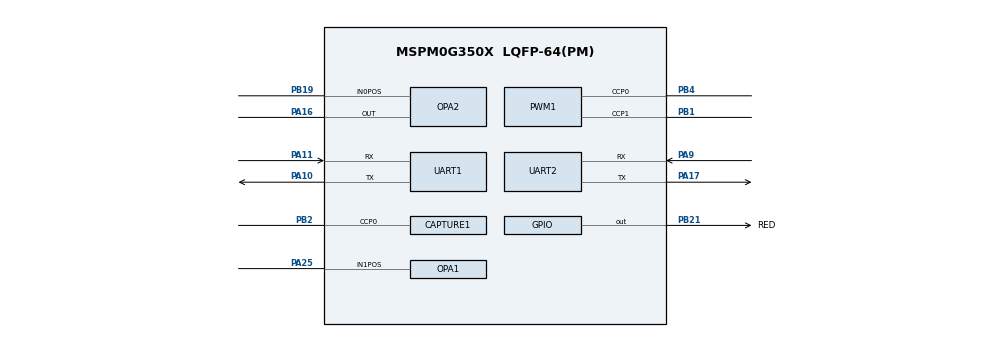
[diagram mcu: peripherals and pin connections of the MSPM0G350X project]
/**
 * @cliArgs --device "MSPM0G350X" --part "Default" --package "LQFP-64(PM)" --product "mspm0_sdk@2.09.00.01"
 * @versions {"tool":"1.25.0+4268"}
 */

/**
 * Import the modules used in this configuration.
 */
const ADC12    = scripting.addModule("/ti/driverlib/ADC12", {}, false);
const ADC121   = ADC12.addInstance();
const CAPTURE  = scripting.addModule("/ti/driverlib/CAPTURE", {}, false);
const CAPTURE1 = CAPTURE.addInstance();
const CRC      = scripting.addModule("/ti/driverlib/CRC");
const GPIO     = scripting.addModule("/ti/driverlib/GPIO", {}, false);
const GPIO1    = GPIO.addInstance();
const OPA      = scripting.addModule("/ti/driverlib/OPA", {}, false);
const OPA1     = OPA.addInstance();
const OPA2     = OPA.addInstance();
const PWM      = scripting.addModule("/ti/driverlib/PWM", {}, false);
const PWM1     = PWM.addInstance();
const RTC      = scripting.addModule("/ti/driverlib/RTC");
const SYSCTL   = scripting.addModule("/ti/driverlib/SYSCTL");
const TIMER    = scripting.addModule("/ti/driverlib/TIMER", {}, false);
const TIMER1   = TIMER.addInstance();
const TIMER2   = TIMER.addInstance();
const TIMER3   = TIMER.addInstance();
const UART     = scripting.addModule("/ti/driverlib/UART", {}, false);
const UART1    = UART.addInstance();
const UART2    = UART.addInstance();

/**
 * Write custom configuration values to the imported modules.
 */
ADC121.$name                             = "WIND_ADC12";
ADC121.sampClkSrc                        = "DL_ADC12_CLOCK_ULPCLK";
ADC121.samplingOperationMode             = "sequence";
ADC121.enabledInterrupts                 = ["DL_ADC12_INTERRUPT_MEM1_RESULT_LOADED"];
ADC121.sampClkDiv                        = "DL_ADC12_CLOCK_DIVIDE_8";
ADC121.powerDownMode                     = "DL_ADC12_POWER_DOWN_MODE_MANUAL";
ADC121.sampleTime0                       = "40 us";
ADC121.endAdd                            = 1;
ADC121.adcMem1chansel                    = "DL_ADC12_INPUT_CHAN_13";
ADC121.peripheral.$assign                = "ADC0";
ADC121.peripheral.adcPin0.$assign        = "PA27";
ADC121.adcPin0Config.hideOutputInversion = scripting.forceWrite(false);
ADC121.adcPin0Config.$name               = "ti_driverlib_gpio_GPIOPinGeneric5";

const Board = scripting.addModule("/ti/driverlib/Board", {}, false);

CAPTURE1.interrupts                         = ["CC0_DN"];
CAPTURE1.timerClkSrc                        = "LFCLK";
CAPTURE1.timerClkPrescale                   = 8;
CAPTURE1.timerPeriod                        = "16.00 s";
CAPTURE1.$name                              = "HALL_EFFECT_CAPTURE";
CAPTURE1.peripheral.$assign                 = "TIMG6";
CAPTURE1.peripheral.ccp0Pin.$assign         = "PB2";
CAPTURE1.ccp0PinConfig.$name                = "ti_driverlib_gpio_GPIOPinGeneric1";
CAPTURE1.ccp0PinConfig.hideOutputInversion  = scripting.forceWrite(false);
CAPTURE1.ccp0PinConfig.onlyInternalResistor = scripting.forceWrite(false);
CAPTURE1.ccp0PinConfig.passedPeripheralType = scripting.forceWrite("Digital");

CRC.seed = 0xFFFFFFFF;

GPIO1.$name                         = "GPIO_LEDS";
GPIO1.port                          = "PORTB";
GPIO1.associatedPins[0].$name       = "RED";
GPIO1.associatedPins[0].assignedPin = "21";
GPIO1.associatedPins[0].pin.$assign = "PB21";

OPA1.$name                        = "OPA_0";
OPA1.cfg0NSELChannel              = "RTOP";
OPA1.cfg0PSELChannel              = "IN1_POS";
OPA1.peripheral.$assign           = "OPA0";
OPA1.peripheral.In1PosPin.$assign = "PA25";
OPA1.In1PosPinConfig.$name        = "ti_driverlib_gpio_GPIOPinGeneric0";

OPA2.$name                        = "OPA_1";
OPA2.cfg0PSELChannel              = "IN0_POS";
OPA2.cfg0NSELChannel              = "RTOP";
OPA2.cfg0OutputPin                = "ENABLED";
OPA2.In0PosPinConfig.$name        = "ti_driverlib_gpio_GPIOPinGeneric6";
OPA2.peripheral.$assign           = "OPA1";
OPA2.peripheral.In0PosPin.$assign = "PB19";
OPA2.peripheral.OutPin.$assign    = "PA16";
OPA2.OutPinConfig.$name           = "ti_driverlib_gpio_GPIOPinGeneric7";

PWM1.$name                              = "SERVO_PWM";
PWM1.clockDivider                       = 8;
PWM1.timerCount                         = 40000;
PWM1.clockPrescale                      = 2;
PWM1.peripheral.ccp0Pin.$assign         = "PB4";
PWM1.peripheral.ccp1Pin.$assign         = "PB1";
PWM1.PWM_CHANNEL_0.$name                = "ti_driverlib_pwm_PWMTimerCC0";
PWM1.PWM_CHANNEL_0.initVal              = "HIGH";
PWM1.PWM_CHANNEL_0.dutyCycle            = 2.5;
PWM1.PWM_CHANNEL_1.$name                = "ti_driverlib_pwm_PWMTimerCC1";
PWM1.PWM_CHANNEL_1.initVal              = "HIGH";
PWM1.PWM_CHANNEL_1.dutyCycle            = 7.5;
PWM1.ccp0PinConfig.direction            = scripting.forceWrite("OUTPUT");
PWM1.ccp0PinConfig.hideOutputInversion  = scripting.forceWrite(false);
PWM1.ccp0PinConfig.onlyInternalResistor = scripting.forceWrite(false);
PWM1.ccp0PinConfig.passedPeripheralType = scripting.forceWrite("Digital");
PWM1.ccp0PinConfig.$name                = "ti_driverlib_gpio_GPIOPinGeneric8";
PWM1.ccp1PinConfig.direction            = scripting.forceWrite("OUTPUT");
PWM1.ccp1PinConfig.hideOutputInversion  = scripting.forceWrite(false);
PWM1.ccp1PinConfig.onlyInternalResistor = scripting.forceWrite(false);
PWM1.ccp1PinConfig.passedPeripheralType = scripting.forceWrite("Digital");
PWM1.ccp1PinConfig.$name                = "ti_driverlib_gpio_GPIOPinGeneric9";

RTC.enableClock = true;

SYSCTL.forceDefaultClkConfig = true;
SYSCTL.clockTreeEn           = true;

TIMER1.timerClkSrc      = "LFCLK";
TIMER1.timerClkPrescale = 8;
TIMER1.$name            = "HALL_EFFECT_TIMEOUT";
TIMER1.interrupts       = ["ZERO"];
TIMER1.timerPeriod      = "2 s";

TIMER2.timerClkDiv      = 2;
TIMER2.timerMode        = "PERIODIC_UP";
TIMER2.timerClkSrc      = "LFCLK";
TIMER2.timerClkPrescale = 256;
TIMER2.interrupts       = ["ZERO"];
TIMER2.$name            = "EVERY_SECOND";
TIMER2.timerPeriod      = "1000 ms";

TIMER3.$name            = "RESET_TIMEOUT";
TIMER3.timerClkSrc      = "LFCLK";
TIMER3.timerClkPrescale = 8;
TIMER3.timerPeriod      = "4 s";
TIMER3.interrupts       = ["ZERO"];

UART1.rxFifoThreshold                   = "DL_UART_RX_FIFO_LEVEL_ONE_ENTRY";
UART1.enabledInterrupts                 = ["DMA_DONE_TX","EOT_DONE"];
UART1.targetBaudRate                    = 115200;
UART1.uartClkDiv                        = "8";
UART1.enableFIFO                        = true;
UART1.txFifoThreshold                   = "DL_UART_TX_FIFO_LEVEL_ONE_ENTRY";
UART1.enabledDMATXTriggers              = "DL_UART_DMA_INTERRUPT_TX";
UART1.$name                             = "UART_DEBUG";
UART1.peripheral.$assign                = "UART0";
UART1.peripheral.rxPin.$assign          = "PA11";
UART1.peripheral.txPin.$assign          = "PA10";
UART1.txPinConfig.direction             = scripting.forceWrite("OUTPUT");
UART1.txPinConfig.hideOutputInversion   = scripting.forceWrite(false);
UART1.txPinConfig.onlyInternalResistor  = scripting.forceWrite(false);
UART1.txPinConfig.passedPeripheralType  = scripting.forceWrite("Digital");
UART1.txPinConfig.$name                 = "ti_driverlib_gpio_GPIOPinGeneric2";
UART1.rxPinConfig.hideOutputInversion   = scripting.forceWrite(false);
UART1.rxPinConfig.onlyInternalResistor  = scripting.forceWrite(false);
UART1.rxPinConfig.passedPeripheralType  = scripting.forceWrite("Digital");
UART1.rxPinConfig.$name                 = "ti_driverlib_gpio_GPIOPinGeneric3";
UART1.DMA_CHANNEL_TX.$name              = "DMA_CH0";
UART1.DMA_CHANNEL_TX.addressMode        = "b2f";
UART1.DMA_CHANNEL_TX.srcLength          = "BYTE";
UART1.DMA_CHANNEL_TX.dstLength          = "BYTE";
UART1.DMA_CHANNEL_TX.peripheral.$assign = "DMA_CH0";

UART2.$name                             = "UART_LOAD";
UART2.enabledDMATXTriggers              = "DL_UART_DMA_INTERRUPT_TX";
UART2.enabledInterrupts                 = ["DMA_DONE_TX","EOT_DONE","RX"];
UART2.peripheral.$assign                = "UART1";
UART2.peripheral.rxPin.$assign          = "PA9";
UART2.peripheral.txPin.$assign          = "PA17";
UART2.txPinConfig.direction             = scripting.forceWrite("OUTPUT");
UART2.txPinConfig.hideOutputInversion   = scripting.forceWrite(false);
UART2.txPinConfig.onlyInternalResistor  = scripting.forceWrite(false);
UART2.txPinConfig.passedPeripheralType  = scripting.forceWrite("Digital");
UART2.txPinConfig.$name                 = "ti_driverlib_gpio_GPIOPinGeneric10";
UART2.rxPinConfig.hideOutputInversion   = scripting.forceWrite(false);
UART2.rxPinConfig.onlyInternalResistor  = scripting.forceWrite(false);
UART2.rxPinConfig.passedPeripheralType  = scripting.forceWrite("Digital");
UART2.rxPinConfig.$name                 = "ti_driverlib_gpio_GPIOPinGeneric11";
UART2.DMA_CHANNEL_TX.$name              = "DMA_CH1";
UART2.DMA_CHANNEL_TX.addressMode        = "b2f";
UART2.DMA_CHANNEL_TX.srcLength          = "BYTE";
UART2.DMA_CHANNEL_TX.dstLength          = "BYTE";
UART2.DMA_CHANNEL_TX.peripheral.$assign = "DMA_CH1";

/**
 * Pinmux solution for unlocked pins/peripherals. This ensures that minor changes to the automatic solver in a future
 * version of the tool will not impact the pinmux you originally saw.  These lines can be completely deleted in order to
 * re-solve from scratch.
 */
Board.peripheral.$suggestSolution          = "DEBUGSS";
Board.peripheral.swclkPin.$suggestSolution = "PA20";
Board.peripheral.swdioPin.$suggestSolution = "PA19";
CRC.peripheral.$suggestSolution            = "CRC";
PWM1.peripheral.$suggestSolution           = "TIMA1";
RTC.peripheral.$suggestSolution            = "RTC";
TIMER1.peripheral.$suggestSolution         = "TIMG7";
TIMER2.peripheral.$suggestSolution         = "TIMG0";
TIMER3.peripheral.$suggestSolution         = "TIMA0";
